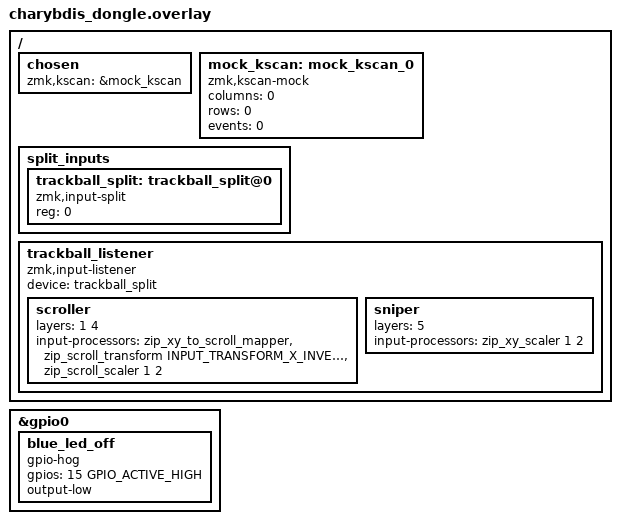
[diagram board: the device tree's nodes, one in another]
/*
 * Dongle: the only central. It has no matrix of its own, so it takes the
 * shared layout and a mock kscan, and receives key positions and trackball
 * motion from the two halves over ESB.
 */

#include "charybdis_layout.dtsi"

#include <zephyr/dt-bindings/input/input-event-codes.h>
#include <input/processors.dtsi>
#include <dt-bindings/zmk/input_transform.h>

/*
 * The board's blue LED on P0.15 blinks continuously on the dongle. Neither ZMK
 * nor the ESB module drives that pin, so nothing turns it off either; hogging
 * it low at boot does. If it still blinks after this, something outside the
 * application is driving it and the pin is not the place to fix it.
 */
&gpio0 {
    blue_led_off {
        gpio-hog;
        gpios = <15 GPIO_ACTIVE_HIGH>;
        output-low;
    };
};

/ {
    chosen {
        zmk,kscan = &mock_kscan;
    };

    mock_kscan: mock_kscan_0 {
        compatible = "zmk,kscan-mock";
        columns = <0>;
        rows = <0>;
        events = <0>;
    };

    /*
     * Proxy for the trackball on the right half. The reg address has to match
     * the zmk,input-split node in charybdis_right.overlay.
     */
    split_inputs {
        #address-cells = <1>;
        #size-cells = <0>;

        trackball_split: trackball_split@0 {
            compatible = "zmk,input-split";
            reg = <0>;
        };
    };

    /*
     * Pointer processing lives here rather than on the half, because layer
     * state is the central's and ZMK only builds the input listener for the
     * central. The right half just forwards raw motion.
     *
     * These have to be the raw layer numbers: keep in sync with the SYMBOLS,
     * SCROLL and SNIPE defines in charybdis.keymap.
     */
    trackball_listener {
        compatible = "zmk,input-listener";
        device = <&trackball_split>;

        scroller {
            /* SYMBOLS and SCROLL */
            layers = <1 4>;
            /* Counts per wheel step. Smooth scrolling makes each step worth
               much less than a full tick, so this has to be far lower than
               the 24 that suited plain ticks: 8 still scrolled too slowly,
               hence 2. Raise it if scrolling now overshoots. */
            input-processors = <&zip_xy_to_scroll_mapper>,
                <&zip_scroll_transform INPUT_TRANSFORM_X_INVERT>,
                <&zip_scroll_scaler 1 2>;
        };

        sniper {
            /* SNIPE */
            layers = <5>;
            input-processors = <&zip_xy_scaler 1 2>;
        };
    };
};
